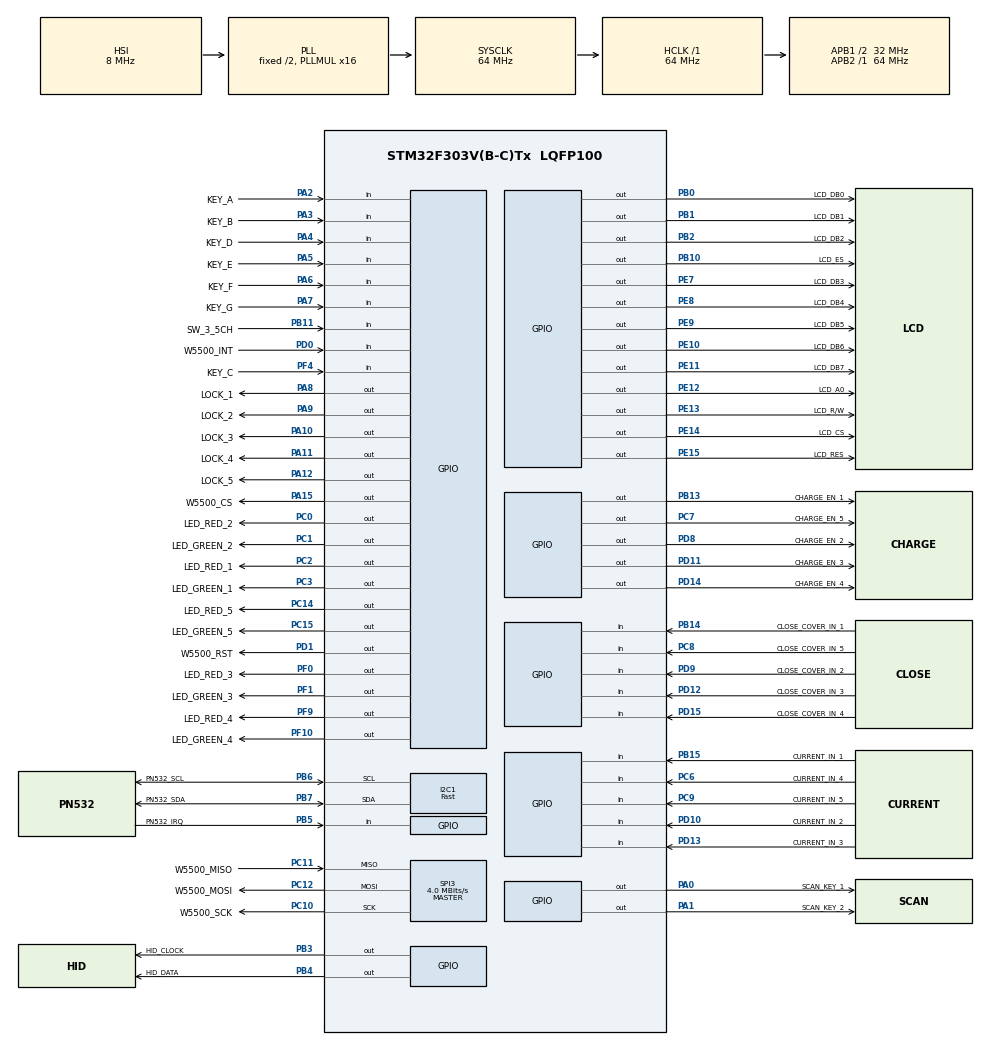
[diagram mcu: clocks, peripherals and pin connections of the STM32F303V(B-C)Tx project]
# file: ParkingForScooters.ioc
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I2C1.I2C_Speed_Mode=I2C_Fast
I2C1.Timing=0x0000020B
Mcu.Family=STM32F3
Mcu.Name=STM32F303V(B-C)Tx
Mcu.Package=LQFP100
NVIC.PriorityGroup=NVIC_PRIORITYGROUP_4
NVIC.TIM3_IRQn=true\:0\:0\:false\:false\:true\:true\:true\:true
PA0.GPIO_Label=SCAN_KEY_1
PA0.GPIO_Speed=GPIO_SPEED_FREQ_HIGH
PA0.Signal=GPIO_Output
PA1.GPIO_Label=SCAN_KEY_2
PA1.GPIO_Speed=GPIO_SPEED_FREQ_HIGH
PA1.Signal=GPIO_Output
PA10.GPIO_Label=LOCK_3
PA10.GPIO_Speed=GPIO_SPEED_FREQ_HIGH
PA10.Signal=GPIO_Output
PA11.GPIO_Label=LOCK_4
PA11.GPIO_Speed=GPIO_SPEED_FREQ_HIGH
PA11.Signal=GPIO_Output
PA12.GPIO_Label=LOCK_5
PA12.GPIO_Speed=GPIO_SPEED_FREQ_HIGH
PA12.Signal=GPIO_Output
PA13.Mode=Serial_Wire
PA13.Signal=SYS_JTMS-SWDIO
PA14.Mode=Serial_Wire
PA14.Signal=SYS_JTCK-SWCLK
PA15.GPIO_Label=W5500_CS
PA15.GPIO_Speed=GPIO_SPEED_FREQ_HIGH
PA15.PinState=GPIO_PIN_SET
PA15.Signal=GPIO_Output
PA2.GPIO_Label=KEY_A
PA2.GPIO_PuPd=GPIO_PULLDOWN
PA2.Signal=GPIO_Input
PA3.GPIO_Label=KEY_B
PA3.GPIO_PuPd=GPIO_PULLDOWN
PA3.Signal=GPIO_Input
PA4.GPIO_Label=KEY_D
PA4.GPIO_PuPd=GPIO_PULLDOWN
PA4.Signal=GPIO_Input
PA5.GPIO_Label=KEY_E
PA5.GPIO_PuPd=GPIO_PULLDOWN
PA5.Signal=GPIO_Input
PA6.GPIO_Label=KEY_F
PA6.GPIO_PuPd=GPIO_PULLDOWN
PA6.Signal=GPIO_Input
PA7.GPIO_Label=KEY_G
PA7.GPIO_PuPd=GPIO_PULLDOWN
PA7.Signal=GPIO_Input
PA8.GPIO_Label=LOCK_1
PA8.GPIO_Speed=GPIO_SPEED_FREQ_HIGH
PA8.Signal=GPIO_Output
PA9.GPIO_Label=LOCK_2
PA9.GPIO_Speed=GPIO_SPEED_FREQ_HIGH
PA9.Signal=GPIO_Output
PB0.GPIO_Label=LCD_DB0
PB0.GPIO_Speed=GPIO_SPEED_FREQ_HIGH
PB0.Signal=GPIO_Output
PB1.GPIO_Label=LCD_DB1
PB1.GPIO_Speed=GPIO_SPEED_FREQ_HIGH
PB1.Signal=GPIO_Output
PB10.GPIO_Label=LCD_ES
PB10.GPIO_Speed=GPIO_SPEED_FREQ_HIGH
PB10.Signal=GPIO_Output
PB11.GPIO_Label=SW_3_5CH
PB11.GPIO_PuPd=GPIO_PULLUP
PB11.Signal=GPIO_Input
PB13.GPIO_Label=CHARGE_EN_1
PB13.Signal=GPIO_Output
PB14.GPIO_Label=CLOSE_COVER_IN_1
PB14.GPIO_PuPd=GPIO_PULLDOWN
PB14.Signal=GPIO_Input
PB15.GPIO_Label=CURRENT_IN_1
PB15.GPIO_PuPd=GPIO_PULLDOWN
PB15.Signal=GPIO_Input
PB2.GPIO_Label=LCD_DB2
PB2.GPIO_Speed=GPIO_SPEED_FREQ_HIGH
PB2.Signal=GPIO_Output
PB3.GPIO_Label=HID_CLOCK
PB3.Signal=GPIO_Output
PB4.GPIO_Label=HID_DATA
PB4.Signal=GPIO_Output
PB5.GPIO_Label=PN532_IRQ
PB5.GPIO_PuPd=GPIO_PULLDOWN
PB5.Signal=GPIO_Input
PB6.GPIO_Label=PN532_SCL
PB6.Mode=I2C
PB6.Signal=I2C1_SCL
PB7.GPIO_Label=PN532_SDA
PB7.Mode=I2C
PB7.Signal=I2C1_SDA
PC0.GPIO_Label=LED_RED_2
PC0.GPIO_Speed=GPIO_SPEED_FREQ_HIGH
PC0.Signal=GPIO_Output
PC1.GPIO_Label=LED_GREEN_2
PC1.GPIO_Speed=GPIO_SPEED_FREQ_HIGH
PC1.Signal=GPIO_Output
PC10.GPIO_Label=W5500_SCK
PC10.Mode=Full_Duplex_Master
PC10.Signal=SPI3_SCK
PC11.GPIO_Label=W5500_MISO
PC11.Mode=Full_Duplex_Master
PC11.Signal=SPI3_MISO
PC12.GPIO_Label=W5500_MOSI
PC12.Mode=Full_Duplex_Master
PC12.Signal=SPI3_MOSI
PC14-OSC32_IN.GPIO_Label=LED_RED_5
PC14-OSC32_IN.Signal=GPIO_Output
PC15-OSC32_OUT.GPIO_Label=LED_GREEN_5
PC15-OSC32_OUT.Signal=GPIO_Output
PC2.GPIO_Label=LED_RED_1
PC2.GPIO_Speed=GPIO_SPEED_FREQ_HIGH
PC2.Signal=GPIO_Output
PC3.GPIO_Label=LED_GREEN_1
PC3.GPIO_Speed=GPIO_SPEED_FREQ_HIGH
PC3.Signal=GPIO_Output
PC6.GPIO_Label=CURRENT_IN_4
PC6.GPIO_PuPd=GPIO_PULLDOWN
PC6.Signal=GPIO_Input
PC7.GPIO_Label=CHARGE_EN_5
PC7.GPIO_Speed=GPIO_SPEED_FREQ_HIGH
PC7.Signal=GPIO_Output
PC8.GPIO_Label=CLOSE_COVER_IN_5
PC8.GPIO_PuPd=GPIO_PULLDOWN
PC8.Signal=GPIO_Input
PC9.GPIO_Label=CURRENT_IN_5
PC9.GPIO_PuPd=GPIO_PULLDOWN
PC9.Signal=GPIO_Input
PD0.GPIO_Label=W5500_INT
PD0.Signal=GPIO_Input
PD1.GPIO_Label=W5500_RST
PD1.Signal=GPIO_Output
PD10.GPIO_Label=CURRENT_IN_2
PD10.GPIO_PuPd=GPIO_PULLDOWN
PD10.Signal=GPIO_Input
PD11.GPIO_Label=CHARGE_EN_3
PD11.GPIO_Speed=GPIO_SPEED_FREQ_HIGH
PD11.Signal=GPIO_Output
PD12.GPIO_Label=CLOSE_COVER_IN_3
PD12.GPIO_PuPd=GPIO_PULLDOWN
PD12.Signal=GPIO_Input
PD13.GPIO_Label=CURRENT_IN_3
PD13.GPIO_PuPd=GPIO_PULLDOWN
PD13.Signal=GPIO_Input
PD14.GPIO_Label=CHARGE_EN_4
PD14.GPIO_Speed=GPIO_SPEED_FREQ_HIGH
PD14.Signal=GPIO_Output
PD15.GPIO_Label=CLOSE_COVER_IN_4
PD15.GPIO_PuPd=GPIO_PULLDOWN
PD15.Signal=GPIO_Input
PD8.GPIO_Label=CHARGE_EN_2
PD8.GPIO_Speed=GPIO_SPEED_FREQ_HIGH
PD8.Signal=GPIO_Output
PD9.GPIO_Label=CLOSE_COVER_IN_2
PD9.GPIO_PuPd=GPIO_PULLDOWN
PD9.Signal=GPIO_Input
PE10.GPIO_Label=LCD_DB6
PE10.GPIO_Speed=GPIO_SPEED_FREQ_HIGH
PE10.Signal=GPIO_Output
PE11.GPIO_Label=LCD_DB7
PE11.GPIO_Speed=GPIO_SPEED_FREQ_HIGH
PE11.Signal=GPIO_Output
PE12.GPIO_Label=LCD_A0
PE12.GPIO_Speed=GPIO_SPEED_FREQ_HIGH
PE12.Signal=GPIO_Output
PE13.GPIO_Label=LCD_R/W
PE13.GPIO_Speed=GPIO_SPEED_FREQ_HIGH
PE13.Signal=GPIO_Output
PE14.GPIO_Label=LCD_CS
PE14.GPIO_Speed=GPIO_SPEED_FREQ_HIGH
PE14.Signal=GPIO_Output
PE15.GPIO_Label=LCD_RES
PE15.GPIO_Speed=GPIO_SPEED_FREQ_HIGH
PE15.Signal=GPIO_Output
PE7.GPIO_Label=LCD_DB3
PE7.GPIO_Speed=GPIO_SPEED_FREQ_HIGH
PE7.Signal=GPIO_Output
PE8.GPIO_Label=LCD_DB4
PE8.GPIO_Speed=GPIO_SPEED_FREQ_HIGH
PE8.Signal=GPIO_Output
PE9.GPIO_Label=LCD_DB5
PE9.GPIO_Speed=GPIO_SPEED_FREQ_HIGH
PE9.Signal=GPIO_Output
PF0-OSC_IN.GPIO_Label=LED_RED_3
PF0-OSC_IN.GPIO_Speed=GPIO_SPEED_FREQ_HIGH
PF0-OSC_IN.Signal=GPIO_Output
PF1-OSC_OUT.GPIO_Label=LED_GREEN_3
PF1-OSC_OUT.GPIO_Speed=GPIO_SPEED_FREQ_HIGH
PF1-OSC_OUT.Signal=GPIO_Output
PF10.GPIO_Label=LED_GREEN_4
PF10.GPIO_Speed=GPIO_SPEED_FREQ_HIGH
PF10.Signal=GPIO_Output
PF4.GPIO_Label=KEY_C
PF4.GPIO_PuPd=GPIO_PULLDOWN
PF4.Signal=GPIO_Input
PF9.GPIO_Label=LED_RED_4
PF9.GPIO_Speed=GPIO_SPEED_FREQ_HIGH
PF9.Signal=GPIO_Output
ProjectManager.HeapSize=0x200
ProjectManager.StackSize=0x400
ProjectManager.TargetToolchain=STM32CubeIDE
RCC.AHBFreq_Value=64000000
RCC.APB1CLKDivider=RCC_HCLK_DIV2
RCC.APB1Freq_Value=32000000
RCC.APB1TimFreq_Value=64000000
RCC.APB2Freq_Value=64000000
RCC.APB2TimFreq_Value=64000000
RCC.CortexFreq_Value=64000000
RCC.HCLKFreq_Value=64000000
RCC.HSE_VALUE=8000000
RCC.HSI_VALUE=8000000
RCC.LSE_VALUE=32768
RCC.PLLMUL=RCC_PLL_MUL16
RCC.SYSCLKFreq_VALUE=64000000
RCC.SYSCLKSourceVirtual=RCC_SYSCLKSOURCE_PLLCLK
RCC.USBFreq_Value=64000000
SPI3.BaudRatePrescaler=SPI_BAUDRATEPRESCALER_8
SPI3.CalculateBaudRate=4.0 MBits/s
SPI3.DataSize=SPI_DATASIZE_8BIT
SPI3.Direction=SPI_DIRECTION_2LINES
SPI3.Mode=SPI_MODE_MASTER
SPI3.VirtualType=VM_MASTER
TIM3.AutoReloadPreload=TIM_AUTORELOAD_PRELOAD_ENABLE
TIM3.Period=999
TIM3.Prescaler=63
TIM3.TIM_MasterOutputTrigger=TIM_TRGO_UPDATE
VP_TIM3_VS_ClockSourceINT.Mode=Internal
board=custom

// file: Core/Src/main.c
/* USER CODE BEGIN Header */
/**
  ******************************************************************************
  * @file           : main.c
  * @brief          : Main program body
  ******************************************************************************
  * @attention
  *
  * Copyright (c) 2022 STMicroelectronics.
  * All rights reserved.
  *
  * This software is licensed under terms that can be found in the LICENSE file
  * in the root directory of this software component.
  * If no LICENSE file comes with this software, it is provided AS-IS.
  *
  ******************************************************************************
  */
/* USER CODE END Header */
#include "main.h"
#include "i2c.h"
#include "spi.h"
#include "tim.h"
#include "gpio.h"

void SystemClock_Config(void);

int main(void)
{

  /* MCU Configuration--------------------------------------------------------*/

  /* Reset of all peripherals, Initializes the Flash interface and the Systick. */
  HAL_Init();

  /* Configure the system clock */
  SystemClock_Config();

  /* Initialize all configured peripherals */
  MX_GPIO_Init();
  MX_TIM3_Init();
  MX_SPI3_Init();
  MX_I2C1_Init();
  /* USER CODE BEGIN 2 */
  startUpSystem();
  /* USER CODE END 2 */

  /* Infinite loop */
  /* USER CODE BEGIN WHILE */
  while (1)
  {
	  tasks();
    /* USER CODE END WHILE */

  }
}

void SystemClock_Config(void)
{
  RCC_OscInitTypeDef RCC_OscInitStruct = {0};
  RCC_ClkInitTypeDef RCC_ClkInitStruct = {0};
  RCC_PeriphCLKInitTypeDef PeriphClkInit = {0};

  /** Initializes the RCC Oscillators according to the specified parameters
  * in the RCC_OscInitTypeDef structure.
  */
  RCC_OscInitStruct.OscillatorType = RCC_OSCILLATORTYPE_HSI;
  RCC_OscInitStruct.HSIState = RCC_HSI_ON;
  RCC_OscInitStruct.HSICalibrationValue = RCC_HSICALIBRATION_DEFAULT;
  RCC_OscInitStruct.PLL.PLLState = RCC_PLL_ON;
  RCC_OscInitStruct.PLL.PLLSource = RCC_PLLSOURCE_HSI;
  RCC_OscInitStruct.PLL.PLLMUL = RCC_PLL_MUL16;
  if (HAL_RCC_OscConfig(&RCC_OscInitStruct) != HAL_OK)
  {
    Error_Handler();
  }

  /** Initializes the CPU, AHB and APB buses clocks
  */
  RCC_ClkInitStruct.ClockType = RCC_CLOCKTYPE_HCLK|RCC_CLOCKTYPE_SYSCLK
                              |RCC_CLOCKTYPE_PCLK1|RCC_CLOCKTYPE_PCLK2;
  RCC_ClkInitStruct.SYSCLKSource = RCC_SYSCLKSOURCE_PLLCLK;
  RCC_ClkInitStruct.AHBCLKDivider = RCC_SYSCLK_DIV1;
  RCC_ClkInitStruct.APB1CLKDivider = RCC_HCLK_DIV2;
  RCC_ClkInitStruct.APB2CLKDivider = RCC_HCLK_DIV1;

  if (HAL_RCC_ClockConfig(&RCC_ClkInitStruct, FLASH_LATENCY_2) != HAL_OK)
  {
    Error_Handler();
  }
  PeriphClkInit.PeriphClockSelection = RCC_PERIPHCLK_I2C1;
  PeriphClkInit.I2c1ClockSelection = RCC_I2C1CLKSOURCE_HSI;
  if (HAL_RCCEx_PeriphCLKConfig(&PeriphClkInit) != HAL_OK)
  {
    Error_Handler();
  }
}

void Error_Handler(void)
{
  __disable_irq();
  while (1)
  {
  }
}
